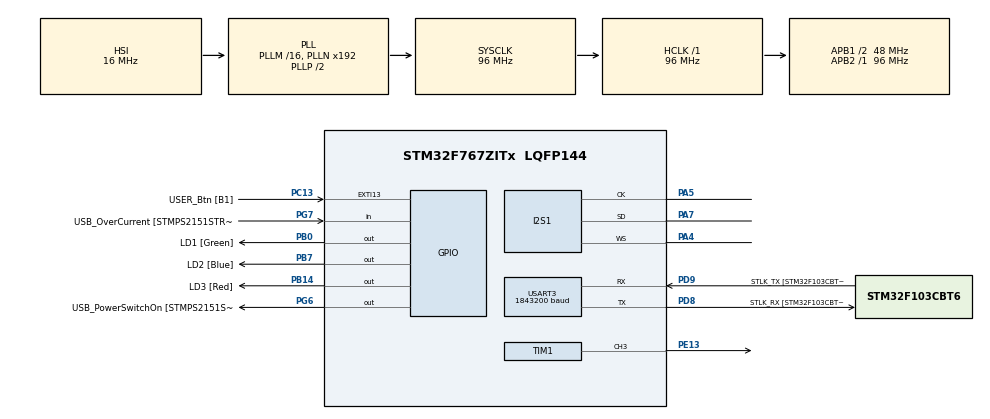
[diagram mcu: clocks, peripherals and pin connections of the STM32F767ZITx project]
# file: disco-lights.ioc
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CORTEX_M7.default_mode_Activation=1
Dma.Request0=SPI1_RX
Dma.Request1=TIM1_CH3
Dma.Request2=USART3_TX
Dma.SPI1_RX.0.Direction=DMA_PERIPH_TO_MEMORY
Dma.SPI1_RX.0.FIFOMode=DMA_FIFOMODE_ENABLE
Dma.SPI1_RX.0.FIFOThreshold=DMA_FIFO_THRESHOLD_FULL
Dma.SPI1_RX.0.Instance=DMA2_Stream0
Dma.SPI1_RX.0.MemBurst=DMA_MBURST_SINGLE
Dma.SPI1_RX.0.MemDataAlignment=DMA_MDATAALIGN_HALFWORD
Dma.SPI1_RX.0.MemInc=DMA_MINC_ENABLE
Dma.SPI1_RX.0.Mode=DMA_CIRCULAR
Dma.SPI1_RX.0.PeriphBurst=DMA_PBURST_SINGLE
Dma.SPI1_RX.0.PeriphDataAlignment=DMA_PDATAALIGN_HALFWORD
Dma.SPI1_RX.0.PeriphInc=DMA_PINC_DISABLE
Dma.SPI1_RX.0.Priority=DMA_PRIORITY_VERY_HIGH
Dma.TIM1_CH3.1.Direction=DMA_MEMORY_TO_PERIPH
Dma.TIM1_CH3.1.FIFOMode=DMA_FIFOMODE_DISABLE
Dma.TIM1_CH3.1.Instance=DMA2_Stream6
Dma.TIM1_CH3.1.MemDataAlignment=DMA_MDATAALIGN_WORD
Dma.TIM1_CH3.1.MemInc=DMA_MINC_ENABLE
Dma.TIM1_CH3.1.Mode=DMA_NORMAL
Dma.TIM1_CH3.1.PeriphDataAlignment=DMA_PDATAALIGN_WORD
Dma.TIM1_CH3.1.PeriphInc=DMA_PINC_DISABLE
Dma.TIM1_CH3.1.Priority=DMA_PRIORITY_VERY_HIGH
Dma.USART3_TX.2.Direction=DMA_MEMORY_TO_PERIPH
Dma.USART3_TX.2.FIFOMode=DMA_FIFOMODE_DISABLE
Dma.USART3_TX.2.Instance=DMA1_Stream3
Dma.USART3_TX.2.MemDataAlignment=DMA_MDATAALIGN_BYTE
Dma.USART3_TX.2.MemInc=DMA_MINC_ENABLE
Dma.USART3_TX.2.Mode=DMA_NORMAL
Dma.USART3_TX.2.PeriphDataAlignment=DMA_PDATAALIGN_BYTE
Dma.USART3_TX.2.PeriphInc=DMA_PINC_DISABLE
Dma.USART3_TX.2.Priority=DMA_PRIORITY_VERY_HIGH
I2S1.AudioFreq=I2S_AUDIOFREQ_44K
I2S1.DataFormat=I2S_DATAFORMAT_16B
I2S1.ErrorAudioFreq=0.26 %
I2S1.FullDuplexMode=I2S_FULLDUPLEXMODE_DISABLE
I2S1.Instance=SPI$Index
I2S1.Mode=I2S_MODE_MASTER_RX
I2S1.RealAudioFreq=44.117 KHz
I2S1.VirtualMode=I2S_MODE_MASTER
Mcu.Family=STM32F7
Mcu.Name=STM32F767ZITx
Mcu.Package=LQFP144
NVIC.DMA1_Stream3_IRQn=true\:0\:0\:false\:false\:true\:false\:true\:true
NVIC.DMA2_Stream0_IRQn=true\:0\:0\:false\:false\:true\:false\:true\:true
NVIC.DMA2_Stream6_IRQn=true\:0\:0\:false\:false\:true\:false\:true\:true
NVIC.PriorityGroup=NVIC_PRIORITYGROUP_4
NVIC.USART3_IRQn=true\:0\:0\:false\:false\:true\:true\:true\:true
PA1.GPIO_Label=RMII_REF_CLK [LAN8742A-CZ-TR_REFCLK0]
PA1.Signal=ETH_REF_CLK
PA10.GPIO_Label=USB_ID
PA10.Signal=USB_OTG_FS_ID
PA11.GPIO_Label=USB_DM
PA11.Signal=USB_OTG_FS_DM
PA12.GPIO_Label=USB_DP
PA12.Signal=USB_OTG_FS_DP
PA13.GPIO_Label=TMS
PA13.Signal=SYS_JTMS-SWDIO
PA14.GPIO_Label=TCK
PA14.Signal=SYS_JTCK-SWCLK
PA2.GPIO_Label=RMII_MDIO [LAN8742A-CZ-TR_MDIO]
PA2.Signal=ETH_MDIO
PA4.Mode=Half_Duplex_Master
PA4.Signal=I2S1_WS
PA5.Mode=Half_Duplex_Master
PA5.Signal=I2S1_CK
PA7.Mode=Half_Duplex_Master
PA7.Signal=I2S1_SD
PA8.GPIO_Label=USB_SOF [TP1]
PA8.Signal=USB_OTG_FS_SOF
PA9.GPIO_Label=USB_VBUS
PA9.Signal=USB_OTG_FS_VBUS
PB0.GPIO_Label=LD1 [Green]
PB0.Signal=GPIO_Output
PB13.GPIO_Label=RMII_TXD1 [LAN8742A-CZ-TR_TXD1]
PB13.Signal=ETH_TXD1
PB14.GPIO_Label=LD3 [Red]
PB14.Signal=GPIO_Output
PB3.GPIO_Label=SW0
PB3.Signal=SYS_JTDO-SWO
PB7.GPIO_Label=LD2 [Blue]
PB7.Signal=GPIO_Output
PC1.GPIO_Label=RMII_MDC [LAN8742A-CZ-TR_MDC]
PC1.Signal=ETH_MDC
PC13.GPIO_Label=USER_Btn [B1]
PC13.Signal=GPXTI13
PC14/OSC32_IN.Signal=RCC_OSC32_IN
PC15/OSC32_OUT.Signal=RCC_OSC32_OUT
PC4.Signal=I2S1_MCK
PC5.GPIO_Label=RMII_RXD1 [LAN8742A-CZ-TR_RXD1]
PC5.Signal=ETH_RXD1
PD8.GPIO_Label=STLK_RX [STM32F103CBT6_PA3]
PD8.Mode=Asynchronous
PD8.Signal=USART3_TX
PD9.GPIO_Label=STLK_TX [STM32F103CBT6_PA2]
PD9.Mode=Asynchronous
PD9.Signal=USART3_RX
PE13.Signal=S_TIM1_CH3
PG11.GPIO_Label=RMII_TX_EN [LAN8742A-CZ-TR_TXEN]
PG11.Signal=ETH_TX_EN
PG13.GPIO_Label=RMII_TXD0 [LAN8742A-CZ-TR_TXD0]
PG13.Signal=ETH_TXD0
PG6.GPIO_Label=USB_PowerSwitchOn [STMPS2151STR_EN]
PG6.Signal=GPIO_Output
PG7.GPIO_Label=USB_OverCurrent [STMPS2151STR_FAULT]
PG7.Signal=GPIO_Input
PH0/OSC_IN.GPIO_Label=MCO [STM32F103CBT6_PA8]
PH0/OSC_IN.Signal=RCC_OSC_IN
PH1/OSC_OUT.Signal=RCC_OSC_OUT
ProjectManager.HeapSize=0x200
ProjectManager.StackSize=0x400
ProjectManager.TargetToolchain=CMake
RCC.48MHZClocksFreq_Value=24000000
RCC.AHBFreq_Value=96000000
RCC.APB1CLKDivider=RCC_HCLK_DIV2
RCC.APB1Freq_Value=48000000
RCC.APB1TimFreq_Value=96000000
RCC.APB2Freq_Value=96000000
RCC.APB2TimFreq_Value=96000000
RCC.CortexFreq_Value=96000000
RCC.HCLKFreq_Value=96000000
RCC.HSE_VALUE=16000000
RCC.HSI_VALUE=16000000
RCC.LSE_VALUE=32768
RCC.PLLMUL=RCC_PLL_MUL9
RCC.PRESCALERUSB=RCC_USBCLKSOURCE_PLL_DIV1_5
RCC.SYSCLKFreq_VALUE=96000000
RCC.SYSCLKSource=RCC_SYSCLKSOURCE_PLLCLK
RCC.SYSCLKSourceVirtual=RCC_SYSCLKSOURCE_PLLCLK
RCC.USBFreq_Value=96000000
RCC.VCOOutputFreq_Value=192000000
SH.S_TIM1_CH3.0=TIM1_CH3,PWM Generation3 CH3
TIM1.Channel-PWM\ Generation3\ CH3=TIM_CHANNEL_3
TIM1.Period=119
USART3.BaudRate=1843200
USART3.VirtualMode-Asynchronous=VM_ASYNC
VP_TIM1_VS_ClockSourceINT.Mode=Internal
board=NUCLEO-F767ZI

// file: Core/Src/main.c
/* USER CODE BEGIN Header */
/**
  ******************************************************************************
  * @file           : main.c
  * @brief          : Main program body
  ******************************************************************************
  * @attention
  *
  * Copyright (c) 2025 STMicroelectronics.
  * All rights reserved.
  *
  * This software is licensed under terms that can be found in the LICENSE file
  * in the root directory of this software component.
  * If no LICENSE file comes with this software, it is provided AS-IS.
  *
  ******************************************************************************
  */
/* USER CODE END Header */
#include "main.h"

I2S_HandleTypeDef hi2s1;
DMA_HandleTypeDef hdma_spi1_rx;

TIM_HandleTypeDef htim1;
DMA_HandleTypeDef hdma_tim1_ch3;

UART_HandleTypeDef huart3;
DMA_HandleTypeDef hdma_usart3_tx;

void SystemClock_Config(void);
static void MPU_Config(void);
static void MX_GPIO_Init(void);
static void MX_DMA_Init(void);
static void MX_I2S1_Init(void);
static void MX_TIM1_Init(void);
static void MX_USART3_UART_Init(void);

int main(void)
{

  /* MPU Configuration--------------------------------------------------------*/
  MPU_Config();

  /* MCU Configuration--------------------------------------------------------*/

  /* Reset of all peripherals, Initializes the Flash interface and the Systick. */
  HAL_Init();

  /* Configure the system clock */
  SystemClock_Config();

  /* Initialize all configured peripherals */
  MX_GPIO_Init();
  MX_DMA_Init();
  MX_I2S1_Init();
  MX_TIM1_Init();
  MX_USART3_UART_Init();
  /* USER CODE BEGIN 2 */
    main_p();
  /* USER CODE END 2 */

  /* Infinite loop */
  while (1)
  {

  }
}

void SystemClock_Config(void)
{
  RCC_OscInitTypeDef RCC_OscInitStruct = {0};
  RCC_ClkInitTypeDef RCC_ClkInitStruct = {0};

  /** Configure the main internal regulator output voltage
  */
  __HAL_RCC_PWR_CLK_ENABLE();
  __HAL_PWR_VOLTAGESCALING_CONFIG(PWR_REGULATOR_VOLTAGE_SCALE3);

  /** Initializes the RCC Oscillators according to the specified parameters
  * in the RCC_OscInitTypeDef structure.
  */
  RCC_OscInitStruct.OscillatorType = RCC_OSCILLATORTYPE_HSI;
  RCC_OscInitStruct.HSIState = RCC_HSI_ON;
  RCC_OscInitStruct.HSICalibrationValue = RCC_HSICALIBRATION_DEFAULT;
  RCC_OscInitStruct.PLL.PLLState = RCC_PLL_ON;
  RCC_OscInitStruct.PLL.PLLSource = RCC_PLLSOURCE_HSI;
  RCC_OscInitStruct.PLL.PLLM = 16;
  RCC_OscInitStruct.PLL.PLLN = 192;
  RCC_OscInitStruct.PLL.PLLP = RCC_PLLP_DIV2;
  RCC_OscInitStruct.PLL.PLLQ = 2;
  RCC_OscInitStruct.PLL.PLLR = 2;
  if (HAL_RCC_OscConfig(&RCC_OscInitStruct) != HAL_OK)
  {
    Error_Handler();
  }

  /** Activate the Over-Drive mode
  */
  if (HAL_PWREx_EnableOverDrive() != HAL_OK)
  {
    Error_Handler();
  }

  /** Initializes the CPU, AHB and APB buses clocks
  */
  RCC_ClkInitStruct.ClockType = RCC_CLOCKTYPE_HCLK|RCC_CLOCKTYPE_SYSCLK
                              |RCC_CLOCKTYPE_PCLK1|RCC_CLOCKTYPE_PCLK2;
  RCC_ClkInitStruct.SYSCLKSource = RCC_SYSCLKSOURCE_PLLCLK;
  RCC_ClkInitStruct.AHBCLKDivider = RCC_SYSCLK_DIV1;
  RCC_ClkInitStruct.APB1CLKDivider = RCC_HCLK_DIV2;
  RCC_ClkInitStruct.APB2CLKDivider = RCC_HCLK_DIV1;

  if (HAL_RCC_ClockConfig(&RCC_ClkInitStruct, FLASH_LATENCY_3) != HAL_OK)
  {
    Error_Handler();
  }
}

static void MX_I2S1_Init(void)
{

  hi2s1.Instance = SPI1;
  hi2s1.Init.Mode = I2S_MODE_MASTER_RX;
  hi2s1.Init.Standard = I2S_STANDARD_PHILIPS;
  hi2s1.Init.DataFormat = I2S_DATAFORMAT_16B;
  hi2s1.Init.MCLKOutput = I2S_MCLKOUTPUT_DISABLE;
  hi2s1.Init.AudioFreq = I2S_AUDIOFREQ_44K;
  hi2s1.Init.CPOL = I2S_CPOL_LOW;
  hi2s1.Init.ClockSource = I2S_CLOCK_PLL;
  if (HAL_I2S_Init(&hi2s1) != HAL_OK)
  {
    Error_Handler();
  }

}

static void MX_TIM1_Init(void)
{

  TIM_ClockConfigTypeDef sClockSourceConfig = {0};
  TIM_MasterConfigTypeDef sMasterConfig = {0};
  TIM_OC_InitTypeDef sConfigOC = {0};
  TIM_BreakDeadTimeConfigTypeDef sBreakDeadTimeConfig = {0};

  htim1.Instance = TIM1;
  htim1.Init.Prescaler = 0;
  htim1.Init.CounterMode = TIM_COUNTERMODE_UP;
  htim1.Init.Period = 119;
  htim1.Init.ClockDivision = TIM_CLOCKDIVISION_DIV1;
  htim1.Init.RepetitionCounter = 0;
  htim1.Init.AutoReloadPreload = TIM_AUTORELOAD_PRELOAD_DISABLE;
  if (HAL_TIM_Base_Init(&htim1) != HAL_OK)
  {
    Error_Handler();
  }
  sClockSourceConfig.ClockSource = TIM_CLOCKSOURCE_INTERNAL;
  if (HAL_TIM_ConfigClockSource(&htim1, &sClockSourceConfig) != HAL_OK)
  {
    Error_Handler();
  }
  if (HAL_TIM_PWM_Init(&htim1) != HAL_OK)
  {
    Error_Handler();
  }
  sMasterConfig.MasterOutputTrigger = TIM_TRGO_RESET;
  sMasterConfig.MasterOutputTrigger2 = TIM_TRGO2_RESET;
  sMasterConfig.MasterSlaveMode = TIM_MASTERSLAVEMODE_DISABLE;
  if (HAL_TIMEx_MasterConfigSynchronization(&htim1, &sMasterConfig) != HAL_OK)
  {
    Error_Handler();
  }
  sConfigOC.OCMode = TIM_OCMODE_PWM1;
  sConfigOC.Pulse = 0;
  sConfigOC.OCPolarity = TIM_OCPOLARITY_HIGH;
  sConfigOC.OCNPolarity = TIM_OCNPOLARITY_HIGH;
  sConfigOC.OCFastMode = TIM_OCFAST_DISABLE;
  sConfigOC.OCIdleState = TIM_OCIDLESTATE_RESET;
  sConfigOC.OCNIdleState = TIM_OCNIDLESTATE_RESET;
  if (HAL_TIM_PWM_ConfigChannel(&htim1, &sConfigOC, TIM_CHANNEL_3) != HAL_OK)
  {
    Error_Handler();
  }
  sBreakDeadTimeConfig.OffStateRunMode = TIM_OSSR_DISABLE;
  sBreakDeadTimeConfig.OffStateIDLEMode = TIM_OSSI_DISABLE;
  sBreakDeadTimeConfig.LockLevel = TIM_LOCKLEVEL_OFF;
  sBreakDeadTimeConfig.DeadTime = 0;
  sBreakDeadTimeConfig.BreakState = TIM_BREAK_DISABLE;
  sBreakDeadTimeConfig.BreakPolarity = TIM_BREAKPOLARITY_HIGH;
  sBreakDeadTimeConfig.BreakFilter = 0;
  sBreakDeadTimeConfig.Break2State = TIM_BREAK2_DISABLE;
  sBreakDeadTimeConfig.Break2Polarity = TIM_BREAK2POLARITY_HIGH;
  sBreakDeadTimeConfig.Break2Filter = 0;
  sBreakDeadTimeConfig.AutomaticOutput = TIM_AUTOMATICOUTPUT_DISABLE;
  if (HAL_TIMEx_ConfigBreakDeadTime(&htim1, &sBreakDeadTimeConfig) != HAL_OK)
  {
    Error_Handler();
  }
  HAL_TIM_MspPostInit(&htim1);

}

static void MX_USART3_UART_Init(void)
{

  huart3.Instance = USART3;
  huart3.Init.BaudRate = 1843200;
  huart3.Init.WordLength = UART_WORDLENGTH_8B;
  huart3.Init.StopBits = UART_STOPBITS_1;
  huart3.Init.Parity = UART_PARITY_NONE;
  huart3.Init.Mode = UART_MODE_TX_RX;
  huart3.Init.HwFlowCtl = UART_HWCONTROL_NONE;
  huart3.Init.OverSampling = UART_OVERSAMPLING_16;
  huart3.Init.OneBitSampling = UART_ONE_BIT_SAMPLE_DISABLE;
  huart3.AdvancedInit.AdvFeatureInit = UART_ADVFEATURE_NO_INIT;
  if (HAL_UART_Init(&huart3) != HAL_OK)
  {
    Error_Handler();
  }

}

static void MX_DMA_Init(void)
{

  /* DMA controller clock enable */
  __HAL_RCC_DMA2_CLK_ENABLE();
  __HAL_RCC_DMA1_CLK_ENABLE();

  /* DMA interrupt init */
  /* DMA1_Stream3_IRQn interrupt configuration */
  HAL_NVIC_SetPriority(DMA1_Stream3_IRQn, 0, 0);
  HAL_NVIC_EnableIRQ(DMA1_Stream3_IRQn);
  /* DMA2_Stream0_IRQn interrupt configuration */
  HAL_NVIC_SetPriority(DMA2_Stream0_IRQn, 0, 0);
  HAL_NVIC_EnableIRQ(DMA2_Stream0_IRQn);
  /* DMA2_Stream6_IRQn interrupt configuration */
  HAL_NVIC_SetPriority(DMA2_Stream6_IRQn, 0, 0);
  HAL_NVIC_EnableIRQ(DMA2_Stream6_IRQn);

}

static void MX_GPIO_Init(void)
{
  GPIO_InitTypeDef GPIO_InitStruct = {0};

  /* GPIO Ports Clock Enable */
  __HAL_RCC_GPIOC_CLK_ENABLE();
  __HAL_RCC_GPIOH_CLK_ENABLE();
  __HAL_RCC_GPIOA_CLK_ENABLE();
  __HAL_RCC_GPIOB_CLK_ENABLE();
  __HAL_RCC_GPIOE_CLK_ENABLE();
  __HAL_RCC_GPIOD_CLK_ENABLE();
  __HAL_RCC_GPIOG_CLK_ENABLE();

  /*Configure GPIO pin Output Level */
  HAL_GPIO_WritePin(GPIOB, LD1_Pin|LD3_Pin|LD2_Pin, GPIO_PIN_RESET);

  /*Configure GPIO pin Output Level */
  HAL_GPIO_WritePin(USB_PowerSwitchOn_GPIO_Port, USB_PowerSwitchOn_Pin, GPIO_PIN_RESET);

  /*Configure GPIO pin : USER_Btn_Pin */
  GPIO_InitStruct.Pin = USER_Btn_Pin;
  GPIO_InitStruct.Mode = GPIO_MODE_IT_RISING;
  GPIO_InitStruct.Pull = GPIO_NOPULL;
  HAL_GPIO_Init(USER_Btn_GPIO_Port, &GPIO_InitStruct);

  /*Configure GPIO pins : RMII_MDC_Pin RMII_RXD1_Pin */
  GPIO_InitStruct.Pin = RMII_MDC_Pin|RMII_RXD1_Pin;
  GPIO_InitStruct.Mode = GPIO_MODE_AF_PP;
  GPIO_InitStruct.Pull = GPIO_NOPULL;
  GPIO_InitStruct.Speed = GPIO_SPEED_FREQ_HIGH;
  GPIO_InitStruct.Alternate = GPIO_AF11_ETH;
  HAL_GPIO_Init(GPIOC, &GPIO_InitStruct);

  /*Configure GPIO pins : RMII_REF_CLK_Pin RMII_MDIO_Pin */
  GPIO_InitStruct.Pin = RMII_REF_CLK_Pin|RMII_MDIO_Pin;
  GPIO_InitStruct.Mode = GPIO_MODE_AF_PP;
  GPIO_InitStruct.Pull = GPIO_NOPULL;
  GPIO_InitStruct.Speed = GPIO_SPEED_FREQ_HIGH;
  GPIO_InitStruct.Alternate = GPIO_AF11_ETH;
  HAL_GPIO_Init(GPIOA, &GPIO_InitStruct);

  /*Configure GPIO pins : LD1_Pin LD3_Pin LD2_Pin */
  GPIO_InitStruct.Pin = LD1_Pin|LD3_Pin|LD2_Pin;
  GPIO_InitStruct.Mode = GPIO_MODE_OUTPUT_PP;
  GPIO_InitStruct.Pull = GPIO_NOPULL;
  GPIO_InitStruct.Speed = GPIO_SPEED_FREQ_LOW;
  HAL_GPIO_Init(GPIOB, &GPIO_InitStruct);

  /*Configure GPIO pin : RMII_TXD1_Pin */
  GPIO_InitStruct.Pin = RMII_TXD1_Pin;
  GPIO_InitStruct.Mode = GPIO_MODE_AF_PP;
  GPIO_InitStruct.Pull = GPIO_NOPULL;
  GPIO_InitStruct.Speed = GPIO_SPEED_FREQ_HIGH;
  GPIO_InitStruct.Alternate = GPIO_AF11_ETH;
  HAL_GPIO_Init(RMII_TXD1_GPIO_Port, &GPIO_InitStruct);

  /*Configure GPIO pin : USB_PowerSwitchOn_Pin */
  GPIO_InitStruct.Pin = USB_PowerSwitchOn_Pin;
  GPIO_InitStruct.Mode = GPIO_MODE_OUTPUT_PP;
  GPIO_InitStruct.Pull = GPIO_NOPULL;
  GPIO_InitStruct.Speed = GPIO_SPEED_FREQ_LOW;
  HAL_GPIO_Init(USB_PowerSwitchOn_GPIO_Port, &GPIO_InitStruct);

  /*Configure GPIO pin : USB_OverCurrent_Pin */
  GPIO_InitStruct.Pin = USB_OverCurrent_Pin;
  GPIO_InitStruct.Mode = GPIO_MODE_INPUT;
  GPIO_InitStruct.Pull = GPIO_NOPULL;
  HAL_GPIO_Init(USB_OverCurrent_GPIO_Port, &GPIO_InitStruct);

  /*Configure GPIO pins : USB_SOF_Pin USB_ID_Pin USB_DM_Pin USB_DP_Pin */
  GPIO_InitStruct.Pin = USB_SOF_Pin|USB_ID_Pin|USB_DM_Pin|USB_DP_Pin;
  GPIO_InitStruct.Mode = GPIO_MODE_AF_PP;
  GPIO_InitStruct.Pull = GPIO_NOPULL;
  GPIO_InitStruct.Speed = GPIO_SPEED_FREQ_VERY_HIGH;
  GPIO_InitStruct.Alternate = GPIO_AF10_OTG_FS;
  HAL_GPIO_Init(GPIOA, &GPIO_InitStruct);

  /*Configure GPIO pin : USB_VBUS_Pin */
  GPIO_InitStruct.Pin = USB_VBUS_Pin;
  GPIO_InitStruct.Mode = GPIO_MODE_INPUT;
  GPIO_InitStruct.Pull = GPIO_NOPULL;
  HAL_GPIO_Init(USB_VBUS_GPIO_Port, &GPIO_InitStruct);

  /*Configure GPIO pins : RMII_TX_EN_Pin RMII_TXD0_Pin */
  GPIO_InitStruct.Pin = RMII_TX_EN_Pin|RMII_TXD0_Pin;
  GPIO_InitStruct.Mode = GPIO_MODE_AF_PP;
  GPIO_InitStruct.Pull = GPIO_NOPULL;
  GPIO_InitStruct.Speed = GPIO_SPEED_FREQ_HIGH;
  GPIO_InitStruct.Alternate = GPIO_AF11_ETH;
  HAL_GPIO_Init(GPIOG, &GPIO_InitStruct);

}

 /* MPU Configuration */

void MPU_Config(void)
{
  MPU_Region_InitTypeDef MPU_InitStruct = {0};

  /* Disables the MPU */
  HAL_MPU_Disable();

  /** Initializes and configures the Region and the memory to be protected
  */
  MPU_InitStruct.Enable = MPU_REGION_ENABLE;
  MPU_InitStruct.Number = MPU_REGION_NUMBER0;
  MPU_InitStruct.BaseAddress = 0x0;
  MPU_InitStruct.Size = MPU_REGION_SIZE_4GB;
  MPU_InitStruct.SubRegionDisable = 0x87;
  MPU_InitStruct.TypeExtField = MPU_TEX_LEVEL0;
  MPU_InitStruct.AccessPermission = MPU_REGION_NO_ACCESS;
  MPU_InitStruct.DisableExec = MPU_INSTRUCTION_ACCESS_DISABLE;
  MPU_InitStruct.IsShareable = MPU_ACCESS_SHAREABLE;
  MPU_InitStruct.IsCacheable = MPU_ACCESS_NOT_CACHEABLE;
  MPU_InitStruct.IsBufferable = MPU_ACCESS_NOT_BUFFERABLE;

  HAL_MPU_ConfigRegion(&MPU_InitStruct);
  /* Enables the MPU */
  HAL_MPU_Enable(MPU_PRIVILEGED_DEFAULT);

}

void Error_Handler(void)
{
  __disable_irq();
  while (1)
  {
  }
}
